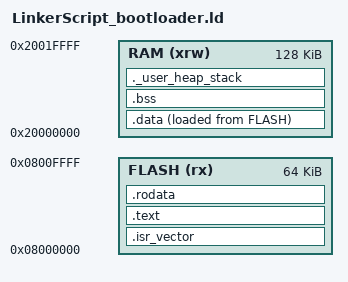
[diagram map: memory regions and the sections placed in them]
/*=============================================================================
  Linker script for STM32F446RE bootloader
  - Bootloader flash size: 64 KB
  - RAM: 128 KB
=============================================================================*/

/* Entry point */
ENTRY(Reset_Handler)

/* Stack/heap sizes */
_Min_Heap_Size = 0x200;
_Min_Stack_Size = 0x400;

/* Stack pointer */
PROVIDE(_estack = ORIGIN(RAM) + LENGTH(RAM));

/* Memories */
MEMORY
{
    FLASH (rx) : ORIGIN = 0x08000000, LENGTH = 64K
    RAM   (xrw) : ORIGIN = 0x20000000, LENGTH = 128K
}

/* Sections */
SECTIONS
{
    /* Vector table and startup code */
    .isr_vector :
    {
        . = ALIGN(4);
        KEEP(*(.isr_vector))
        . = ALIGN(4);
    } >FLASH

    /* Code and read-only data */
    .text :
    {
        . = ALIGN(4);
        *(.text)
        *(.text*)
        *(.glue_7)
        *(.glue_7t)
        *(.eh_frame)
        KEEP(*(.init))
        KEEP(*(.fini))
        . = ALIGN(4);
        _etext = .;
    } >FLASH

    .rodata :
    {
        . = ALIGN(4);
        *(.rodata)
        *(.rodata*)
        . = ALIGN(4);
    } >FLASH

    /* _sidata: used by startup to initialize .data */
    _sidata = LOADADDR(.data);

    /* Initialized data copied to RAM at startup */
    .data :
    {
        . = ALIGN(4);
        _sdata = .;
        *(.data)
        *(.data*)
        . = ALIGN(4);
        _edata = .;
    } >RAM AT> FLASH

    /* Uninitialized data in RAM */
    .bss :
    {
        . = ALIGN(4);
        _sbss = .;
        *(.bss)
        *(.bss*)
        *(COMMON)
        . = ALIGN(4);
        _ebss = .;
    } >RAM

    /* Heap + stack */
    ._user_heap_stack :
    {
        . = ALIGN(8);
        PROVIDE ( end = . );
        PROVIDE ( _end = . );
        . = . + _Min_Heap_Size;
        . = . + _Min_Stack_Size;
        . = ALIGN(8);
    } >RAM

    /* Discard unnecessary library sections */
    /DISCARD/ :
    {
        libc.a(*)
        libm.a(*)
        libgcc.a(*)
    }
}
